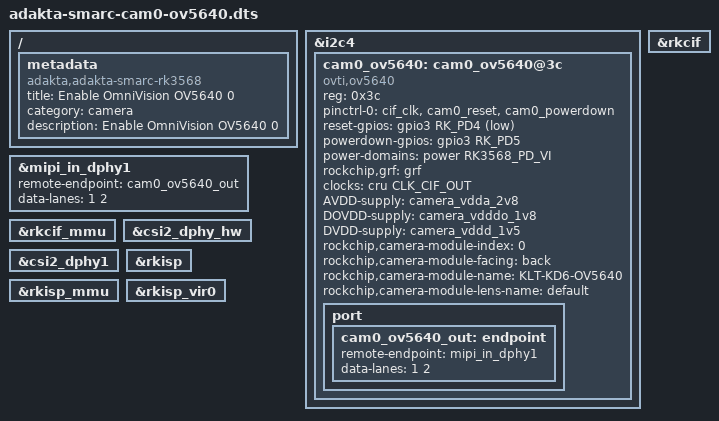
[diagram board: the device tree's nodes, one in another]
/dts-v1/;
/plugin/;

#include <dt-bindings/clock/rk3568-cru.h>
#include <dt-bindings/power/rk3568-power.h>
#include <dt-bindings/gpio/gpio.h>
#include <dt-bindings/pinctrl/rockchip.h>

/ {
	metadata {
		title = "Enable OmniVision OV5640 0";
		compatible = "adakta,adakta-smarc-rk3568";
		category = "camera";
		description = "Enable OmniVision OV5640 0";
	};

	fragment@0 {
		target = <&i2c4>;

		__overlay__ {
			status = "okay";

			cam0_ov5640: cam0_ov5640@3c {
				status = "okay";

				compatible = "ovti,ov5640";
				reg = <0x3c>;

				pinctrl-names = "default";
				pinctrl-0 = <&cif_clk>, <&cam0_reset &cam0_powerdown>;

				reset-gpios = <&gpio3 RK_PD4 GPIO_ACTIVE_LOW>;
				powerdown-gpios = <&gpio3 RK_PD5 GPIO_ACTIVE_HIGH>;

				power-domains = <&power RK3568_PD_VI>;
				rockchip,grf = <&grf>;

				clocks = <&cru CLK_CIF_OUT>;
				clock-names = "xclk";

				AVDD-supply = <&camera_vdda_2v8>;
				DOVDD-supply = <&camera_vdddo_1v8>;
				DVDD-supply = <&camera_vddd_1v5>;

				rockchip,camera-module-index = <0>;
				rockchip,camera-module-facing = "back";
				rockchip,camera-module-name = "KLT-KD6-OV5640";
				rockchip,camera-module-lens-name = "default";

				port {
					cam0_ov5640_out: endpoint {
						remote-endpoint = <&mipi_in_dphy1>;
						data-lanes = <1 2>;
					};
				};
			};
		};
	};

	fragment@1 {
		target = <&mipi_in_dphy1>;

		__overlay__ {
			remote-endpoint = <&cam0_ov5640_out>;
			data-lanes = <1 2>;
		};
	};

	fragment@2 {
		target = <&rkcif>;

		__overlay__ {
			status = "okay";
		};
	};

	fragment@3 {
		target = <&rkcif_mmu>;

		__overlay__ {
			status = "okay";
		};
	};

	fragment@4 {
		target = <&csi2_dphy_hw>;

		__overlay__ {
			status = "okay";
		};
	};

	fragment@5 {
		target = <&csi2_dphy1>;

		__overlay__ {
			status = "okay";
		};
	};

	fragment@6 {
		target = <&rkisp>;

		__overlay__ {
			status = "okay";
		};
	};

	fragment@7 {
		target = <&rkisp_mmu>;

		__overlay__ {
			status = "okay";
		};
	};

	fragment@8 {
		target = <&rkisp_vir0>;

		__overlay__ {
			status = "okay";
		};
	};
};
